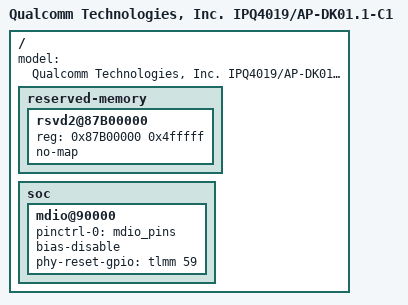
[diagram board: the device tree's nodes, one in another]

/* Copyright (c) 2016, The Linux Foundation. All rights reserved.
 *
 * Permission to use, copy, modify, and/or distribute this software for any
 * purpose with or without fee is hereby granted, provided that the above
 * copyright notice and this permission notice appear in all copies.
 *
 * THE SOFTWARE IS PROVIDED "AS IS" AND THE AUTHOR DISCLAIMS ALL WARRANTIES
 * WITH REGARD TO THIS SOFTWARE INCLUDING ALL IMPLIED WARRANTIES OF
 * MERCHANTABILITY AND FITNESS. IN NO EVENT SHALL THE AUTHOR BE LIABLE FOR
 * ANY SPECIAL, DIRECT, INDIRECT, OR CONSEQUENTIAL DAMAGES OR ANY DAMAGES
 * WHATSOEVER RESULTING FROM LOSS OF USE, DATA OR PROFITS, WHETHER IN AN
 * ACTION OF CONTRACT, NEGLIGENCE OR OTHER TORTIOUS ACTION, ARISING OUT OF
 * OR IN CONNECTION WITH THE USE OR PERFORMANCE OF THIS SOFTWARE.
 *
 */

#include "qcom-ipq4019-ap.dk01.1.dtsi"

/ {
	model = "Qualcomm Technologies, Inc. IPQ4019/AP-DK01.1-C1";

	reserved-memory {
		#address-cells = <1>;
		#size-cells = <1>;
		ranges;
		rsvd2@87B00000 {
			/* Reserved for other subsystem */
			reg = <0x87B00000 0x4fffff>;
			no-map;
		};
	};

	soc {
		mdio@90000 {
			status = "ok";
			pinctrl-0 = <&mdio_pins>;
			pinctrl-names = "default";
			bias-disable;
			phy-reset-gpio = <&tlmm 59 0>;
		};
	};
};
